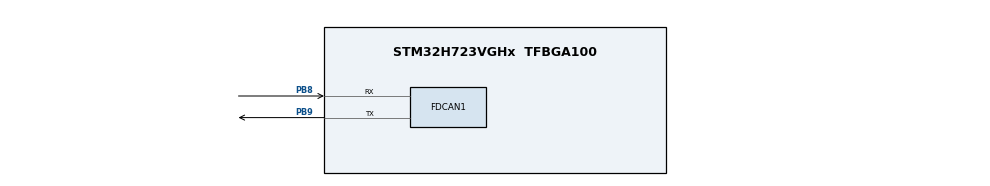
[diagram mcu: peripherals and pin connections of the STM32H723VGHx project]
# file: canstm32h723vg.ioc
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CORTEX_M7.default_mode_Activation=1
FDCAN1.AutoRetransmission=ENABLE
FDCAN1.CalculateBaudRateNominal=1000000
FDCAN1.CalculateTimeBitNominal=1000
FDCAN1.CalculateTimeQuantumNominal=62.5
FDCAN1.DataPrescaler=5
FDCAN1.DataTimeSeg1=13
FDCAN1.DataTimeSeg2=2
FDCAN1.ExtFiltersNbr=0
FDCAN1.NominalPrescaler=5
FDCAN1.NominalTimeSeg1=13
FDCAN1.NominalTimeSeg2=2
FDCAN1.RxFifo0ElmtsNbr=4
FDCAN1.StdFiltersNbr=1
FDCAN1.TxFifoQueueElmtsNbr=3
Mcu.Family=STM32H7
Mcu.Name=STM32H723VGHx
Mcu.Package=TFBGA100
NVIC.FDCAN1_IT0_IRQn=true\:0\:0\:false\:false\:true\:true\:true\:true
NVIC.PriorityGroup=NVIC_PRIORITYGROUP_4
PB8.Mode=FDCAN_Activate
PB8.Signal=FDCAN1_RX
PB9.Mode=FDCAN_Activate
PB9.Signal=FDCAN1_TX
PH0-OSC_IN.Mode=HSE-External-Oscillator
PH0-OSC_IN.Signal=RCC_OSC_IN
PH1-OSC_OUT.Mode=HSE-External-Oscillator
PH1-OSC_OUT.Signal=RCC_OSC_OUT
ProjectManager.HeapSize=0x200
ProjectManager.StackSize=0x400
ProjectManager.TargetToolchain=MDK-ARM V5.32
RCC.ADCFreq_Value=129000000
RCC.APB1Freq_Value=64000000
RCC.APB2Freq_Value=64000000
RCC.APB3Freq_Value=64000000
RCC.APB4Freq_Value=64000000
RCC.CortexFreq_Value=64000000
RCC.DIVM1=4
RCC.DIVN1=15
RCC.DIVQ1=3
RCC.HCLKFreq_Value=64000000
RCC.PLL2FRACN=0
RCC.PLL3FRACN=0
RCC.PLLFRACN=0
RCC.SYSCLKFreq_VALUE=64000000
RCC.USBFreq_Value=80000000
VP_MEMORYMAP_VS_MEMORYMAP.Mode=CurAppReg
board=custom

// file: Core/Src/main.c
/* USER CODE BEGIN Header */
/**
  ******************************************************************************
  * @file           : main.c
  * @brief          : Main program body
  ******************************************************************************
  * @attention
  *
  * Copyright (c) 2026 STMicroelectronics.
  * All rights reserved.
  *
  * This software is licensed under terms that can be found in the LICENSE file
  * in the root directory of this software component.
  * If no LICENSE file comes with this software, it is provided AS-IS.
  *
  ******************************************************************************
  */
/* USER CODE END Header */
#include "main.h"
#include "fdcan.h"
#include "gpio.h"

/* USER CODE BEGIN Includes */
extern FDCAN_HandleTypeDef hfdcan1;
/* USER CODE END Includes */

void SystemClock_Config(void);
static void MPU_Config(void);

/* USER CODE BEGIN 0 */
typedef struct {
  int16_t voltage;
  int16_t angle;
  int16_t speed;
  int16_t current;
  int16_t tempereture;

}GM6020_struct;
GM6020_struct GM6020;
//掩码模式过滤器
static void FDCAN_Filter_Init(FDCAN_HandleTypeDef *h)
{
    FDCAN_FilterTypeDef f = {0};
    f.IdType = FDCAN_STANDARD_ID;
    f.FilterIndex = 0;
    f.FilterType = FDCAN_FILTER_MASK;
    f.FilterConfig = FDCAN_FILTER_TO_RXFIFO0;
    f.FilterID1 = 0x200;
    f.FilterID2 = 0x7F0;
    HAL_FDCAN_ConfigFilter(h, &f);

    HAL_FDCAN_ConfigGlobalFilter(h, FDCAN_REJECT, FDCAN_REJECT,
                                 FDCAN_REJECT_REMOTE, FDCAN_REJECT_REMOTE);
}
void FDCAN_Start(FDCAN_HandleTypeDef *h)
{
    HAL_FDCAN_Start(h);
    HAL_FDCAN_ActivateNotification(h, FDCAN_IT_RX_FIFO0_NEW_MESSAGE, 0);
}
uint8_t FDCAN_SendStd(FDCAN_HandleTypeDef *h, uint16_t id, uint8_t *data)
{
    FDCAN_TxHeaderTypeDef tx = {0};
    tx.Identifier = id;
    tx.IdType = FDCAN_STANDARD_ID;
    tx.TxFrameType = FDCAN_DATA_FRAME;
    tx.DataLength = FDCAN_DLC_BYTES_8;
    tx.ErrorStateIndicator = FDCAN_ESI_ACTIVE;
    tx.BitRateSwitch = FDCAN_BRS_OFF;
    tx.FDFormat = FDCAN_CLASSIC_CAN;
    tx.TxEventFifoControl = FDCAN_NO_TX_EVENTS;
    tx.MessageMarker = 0;

    if (HAL_FDCAN_GetTxFifoFreeLevel(h) == 0) return 2;
    return (HAL_FDCAN_AddMessageToTxFifoQ(h, &tx, data) == HAL_OK) ? 0 : 3;
}

/* USER CODE END 0 */

int main(void)
{

  /* MPU Configuration--------------------------------------------------------*/
  MPU_Config();

  /* MCU Configuration--------------------------------------------------------*/

  /* Reset of all peripherals, Initializes the Flash interface and the Systick. */
  HAL_Init();

  /* Configure the system clock */
  SystemClock_Config();

  /* Initialize all configured peripherals */
  MX_GPIO_Init();
  MX_FDCAN1_Init();
  /* USER CODE BEGIN 2 */
  FDCAN_Filter_Init(&hfdcan1);
  FDCAN_Start(&hfdcan1);
  uint32_t t = 0;
  uint8_t tx[8];
  FDCAN_TxHeaderTypeDef th;
  /* USER CODE END 2 */

  /* Infinite loop */
  /* USER CODE BEGIN WHILE */
  while (1)
  {
    if (HAL_GetTick() - t >= 2)
    {
        t = HAL_GetTick();
        GM6020.voltage = 3000;
        tx[0] = 0x0B;
        tx[1] = 0xB8;

        FDCAN_SendStd(&hfdcan1, 0x1FF, tx);
    }
    /* USER CODE END WHILE */

  }
}

void SystemClock_Config(void)
{
  RCC_OscInitTypeDef RCC_OscInitStruct = {0};
  RCC_ClkInitTypeDef RCC_ClkInitStruct = {0};

  /** Supply configuration update enable
  */
  HAL_PWREx_ConfigSupply(PWR_LDO_SUPPLY);

  /** Configure the main internal regulator output voltage
  */
  __HAL_PWR_VOLTAGESCALING_CONFIG(PWR_REGULATOR_VOLTAGE_SCALE3);

  while(!__HAL_PWR_GET_FLAG(PWR_FLAG_VOSRDY)) {}

  /** Initializes the RCC Oscillators according to the specified parameters
  * in the RCC_OscInitTypeDef structure.
  */
  RCC_OscInitStruct.OscillatorType = RCC_OSCILLATORTYPE_HSI;
  RCC_OscInitStruct.HSIState = RCC_HSI_DIV1;
  RCC_OscInitStruct.HSICalibrationValue = 64;
  RCC_OscInitStruct.PLL.PLLState = RCC_PLL_ON;
  RCC_OscInitStruct.PLL.PLLSource = RCC_PLLSOURCE_HSI;
  RCC_OscInitStruct.PLL.PLLM = 4;
  RCC_OscInitStruct.PLL.PLLN = 15;
  RCC_OscInitStruct.PLL.PLLP = 2;
  RCC_OscInitStruct.PLL.PLLQ = 3;
  RCC_OscInitStruct.PLL.PLLR = 2;
  RCC_OscInitStruct.PLL.PLLRGE = RCC_PLL1VCIRANGE_3;
  RCC_OscInitStruct.PLL.PLLVCOSEL = RCC_PLL1VCOWIDE;
  RCC_OscInitStruct.PLL.PLLFRACN = 0;
  if (HAL_RCC_OscConfig(&RCC_OscInitStruct) != HAL_OK)
  {
    Error_Handler();
  }

  /** Initializes the CPU, AHB and APB buses clocks
  */
  RCC_ClkInitStruct.ClockType = RCC_CLOCKTYPE_HCLK|RCC_CLOCKTYPE_SYSCLK
                              |RCC_CLOCKTYPE_PCLK1|RCC_CLOCKTYPE_PCLK2
                              |RCC_CLOCKTYPE_D3PCLK1|RCC_CLOCKTYPE_D1PCLK1;
  RCC_ClkInitStruct.SYSCLKSource = RCC_SYSCLKSOURCE_HSI;
  RCC_ClkInitStruct.SYSCLKDivider = RCC_SYSCLK_DIV1;
  RCC_ClkInitStruct.AHBCLKDivider = RCC_HCLK_DIV1;
  RCC_ClkInitStruct.APB3CLKDivider = RCC_APB3_DIV1;
  RCC_ClkInitStruct.APB1CLKDivider = RCC_APB1_DIV1;
  RCC_ClkInitStruct.APB2CLKDivider = RCC_APB2_DIV1;
  RCC_ClkInitStruct.APB4CLKDivider = RCC_APB4_DIV1;

  if (HAL_RCC_ClockConfig(&RCC_ClkInitStruct, FLASH_LATENCY_1) != HAL_OK)
  {
    Error_Handler();
  }
}

/* USER CODE BEGIN 4 */
void HAL_FDCAN_RxFifo0Callback(FDCAN_HandleTypeDef *hfdcan, uint32_t RxFifo0ITs)
{
    FDCAN_RxHeaderTypeDef rx;
    uint8_t d[8];

    while (HAL_FDCAN_GetRxFifoFillLevel(hfdcan, FDCAN_RX_FIFO0) > 0)
    {
        if (HAL_FDCAN_GetRxMessage(hfdcan, FDCAN_RX_FIFO0, &rx, d) == HAL_OK)
        {
            if (rx.IdType == FDCAN_STANDARD_ID &&
                rx.Identifier >= 0x205 && rx.Identifier <= 0x20B)
            {
                GM6020.angle       = (int16_t)((d[0] << 8) | d[1]);
                GM6020.speed       = (int16_t)((d[2] << 8) | d[3]);
                GM6020.current     = (int16_t)((d[4] << 8) | d[5]);
                GM6020.tempereture = d[6];
            }
        }
    }
}
/* USER CODE END 4 */

 /* MPU Configuration */

void MPU_Config(void)
{
  MPU_Region_InitTypeDef MPU_InitStruct = {0};

  /* Disables the MPU */
  HAL_MPU_Disable();

  /** Initializes and configures the Region and the memory to be protected
  */
  MPU_InitStruct.Enable = MPU_REGION_ENABLE;
  MPU_InitStruct.Number = MPU_REGION_NUMBER0;
  MPU_InitStruct.BaseAddress = 0x0;
  MPU_InitStruct.Size = MPU_REGION_SIZE_4GB;
  MPU_InitStruct.SubRegionDisable = 0x87;
  MPU_InitStruct.TypeExtField = MPU_TEX_LEVEL0;
  MPU_InitStruct.AccessPermission = MPU_REGION_NO_ACCESS;
  MPU_InitStruct.DisableExec = MPU_INSTRUCTION_ACCESS_DISABLE;
  MPU_InitStruct.IsShareable = MPU_ACCESS_SHAREABLE;
  MPU_InitStruct.IsCacheable = MPU_ACCESS_NOT_CACHEABLE;
  MPU_InitStruct.IsBufferable = MPU_ACCESS_NOT_BUFFERABLE;

  HAL_MPU_ConfigRegion(&MPU_InitStruct);
  /* Enables the MPU */
  HAL_MPU_Enable(MPU_PRIVILEGED_DEFAULT);

}

void Error_Handler(void)
{
  __disable_irq();
  while (1)
  {
  }
}
